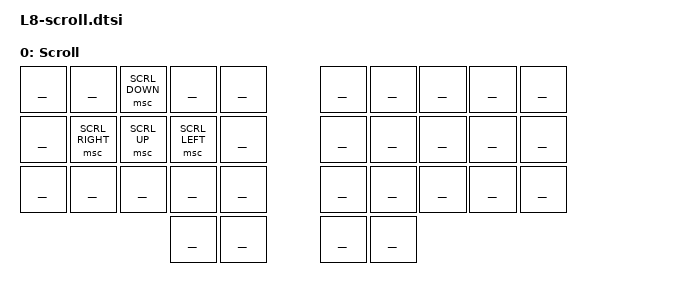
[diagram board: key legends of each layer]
/**
 * Held with the M key on the Mouse layer: the pointer keys (E S D F) scroll instead.
 * Every other key falls through to the Mouse layer.
 */

/ {
  keymap {
    compatible = "zmk,keymap";

	scroll_layer {
		label = "Scroll";
		bindings = <
//	╭───────────────┬───────────────┬───────────────┬───────────────┬───────────────╮   ╭───────────────┬───────────────┬───────────────┬───────────────┬───────────────╮
	________        ________        &msc SCRL_DOWN  ________        ________            ________        ________        ________        ________        ________
//	├───────────────┼───────────────┼───────────────┼───────────────┼───────────────┤   ├───────────────├───────────────┼───────────────┼───────────────┼───────────────┤
	________        &msc SCRL_RIGHT &msc SCRL_UP    &msc SCRL_LEFT  ________            ________        ________        ________        ________        ________
//	├───────────────┼───────────────┼───────────────┼───────────────┼───────────────┤   ├───────────────├───────────────┼───────────────┼───────────────┼───────────────┤
	________		________        ________        ________		________            ________        ________     	________        ________        ________
//	╰───────────────┴───────────────┼───────────────┼───────────────┼───────────────┤   ├───────────────├───────────────┼───────────────┼───────────────┴───────────────╯
	       											________        ________           	________		________
//                                                  ╰───────────────┴───────────────╯   ╰───────────────┴───────────────╯
			>;
		};
	};
};
